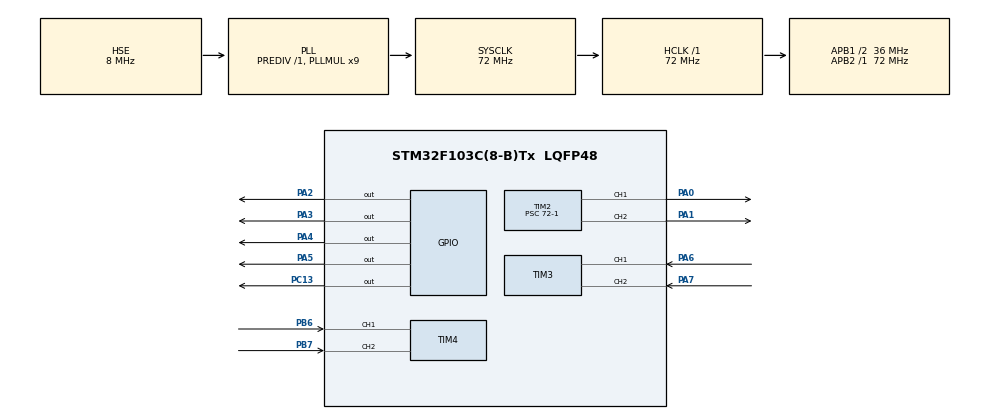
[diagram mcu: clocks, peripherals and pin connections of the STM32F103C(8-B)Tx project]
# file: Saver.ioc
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FREERTOS.Tasks01=defaultTask,0,128,StartDefaultTask,Default,NULL,Dynamic,NULL,NULL
Mcu.Family=STM32F1
Mcu.Name=STM32F103C(8-B)Tx
Mcu.Package=LQFP48
NVIC.PriorityGroup=NVIC_PRIORITYGROUP_4
NVIC.TIM3_IRQn=true\:5\:0\:false\:false\:true\:true\:true\:true\:true
NVIC.TIM4_IRQn=true\:5\:0\:false\:false\:true\:true\:true\:true\:true
PA0-WKUP.Signal=S_TIM2_CH1_ETR
PA1.Signal=S_TIM2_CH2
PA13.Mode=Serial_Wire
PA13.Signal=SYS_JTMS-SWDIO
PA14.Mode=Serial_Wire
PA14.Signal=SYS_JTCK-SWCLK
PA2.Signal=GPIO_Output
PA3.Signal=GPIO_Output
PA4.Signal=GPIO_Output
PA5.Signal=GPIO_Output
PA6.Signal=S_TIM3_CH1
PA7.Signal=S_TIM3_CH2
PB6.Signal=S_TIM4_CH1
PB7.Signal=S_TIM4_CH2
PC13-TAMPER-RTC.Signal=GPIO_Output
PD0-OSC_IN.Mode=HSE-External-Oscillator
PD0-OSC_IN.Signal=RCC_OSC_IN
PD1-OSC_OUT.Mode=HSE-External-Oscillator
PD1-OSC_OUT.Signal=RCC_OSC_OUT
ProjectManager.HeapSize=0x200
ProjectManager.StackSize=0x400
ProjectManager.TargetToolchain=MDK-ARM V5.32
RCC.AHBFreq_Value=72000000
RCC.APB1CLKDivider=RCC_HCLK_DIV2
RCC.APB1Freq_Value=36000000
RCC.APB1TimFreq_Value=72000000
RCC.APB2Freq_Value=72000000
RCC.APB2TimFreq_Value=72000000
RCC.HCLKFreq_Value=72000000
RCC.PLLMUL=RCC_PLL_MUL9
RCC.PLLSourceVirtual=RCC_PLLSOURCE_HSE
RCC.SYSCLKFreq_VALUE=72000000
RCC.SYSCLKSource=RCC_SYSCLKSOURCE_PLLCLK
RCC.USBFreq_Value=72000000
SH.S_TIM2_CH1_ETR.0=TIM2_CH1,PWM Generation1 CH1
SH.S_TIM2_CH2.0=TIM2_CH2,PWM Generation2 CH2
SH.S_TIM3_CH1.0=TIM3_CH1,Encoder_Interface
SH.S_TIM3_CH2.0=TIM3_CH2,Encoder_Interface
SH.S_TIM4_CH1.0=TIM4_CH1,Encoder_Interface
SH.S_TIM4_CH2.0=TIM4_CH2,Encoder_Interface
TIM2.Channel-PWM\ Generation1\ CH1=TIM_CHANNEL_1
TIM2.Channel-PWM\ Generation2\ CH2=TIM_CHANNEL_2
TIM2.Period=2000-1
TIM2.Prescaler=72-1
TIM3.EncoderMode=TIM_ENCODERMODE_TI12
TIM4.EncoderMode=TIM_ENCODERMODE_TI12
VP_FREERTOS_VS_CMSIS_V1.Mode=CMSIS_V1
board=custom

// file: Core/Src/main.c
/* USER CODE BEGIN Header */
/**
  ******************************************************************************
  * @file           : main.c
  * @brief          : Main program body
  ******************************************************************************
  * @attention
  *
  * Copyright (c) 2024 STMicroelectronics.
  * All rights reserved.
  *
  * This software is licensed under terms that can be found in the LICENSE file
  * in the root directory of this software component.
  * If no LICENSE file comes with this software, it is provided AS-IS.
  *
  ******************************************************************************
  */
/* USER CODE END Header */
#include "main.h"
#include "cmsis_os.h"
#include "tim.h"
#include "gpio.h"

void SystemClock_Config(void);
void MX_FREERTOS_Init(void);

int main(void)
{

  /* MCU Configuration--------------------------------------------------------*/

  /* Reset of all peripherals, Initializes the Flash interface and the Systick. */
  HAL_Init();

  /* Configure the system clock */
  SystemClock_Config();

  /* Initialize all configured peripherals */
  MX_GPIO_Init();
  MX_TIM2_Init();
  MX_TIM3_Init();
  MX_TIM4_Init();

  /* Call init function for freertos objects (in cmsis_os2.c) */
  MX_FREERTOS_Init();

  /* Start scheduler */
  osKernelStart();

  /* We should never get here as control is now taken by the scheduler */

  /* Infinite loop */
  while (1)
  {

  }
}

void SystemClock_Config(void)
{
  RCC_OscInitTypeDef RCC_OscInitStruct = {0};
  RCC_ClkInitTypeDef RCC_ClkInitStruct = {0};

  /** Initializes the RCC Oscillators according to the specified parameters
  * in the RCC_OscInitTypeDef structure.
  */
  RCC_OscInitStruct.OscillatorType = RCC_OSCILLATORTYPE_HSE;
  RCC_OscInitStruct.HSEState = RCC_HSE_ON;
  RCC_OscInitStruct.HSEPredivValue = RCC_HSE_PREDIV_DIV1;
  RCC_OscInitStruct.HSIState = RCC_HSI_ON;
  RCC_OscInitStruct.PLL.PLLState = RCC_PLL_ON;
  RCC_OscInitStruct.PLL.PLLSource = RCC_PLLSOURCE_HSE;
  RCC_OscInitStruct.PLL.PLLMUL = RCC_PLL_MUL9;
  if (HAL_RCC_OscConfig(&RCC_OscInitStruct) != HAL_OK)
  {
    Error_Handler();
  }

  /** Initializes the CPU, AHB and APB buses clocks
  */
  RCC_ClkInitStruct.ClockType = RCC_CLOCKTYPE_HCLK|RCC_CLOCKTYPE_SYSCLK
                              |RCC_CLOCKTYPE_PCLK1|RCC_CLOCKTYPE_PCLK2;
  RCC_ClkInitStruct.SYSCLKSource = RCC_SYSCLKSOURCE_PLLCLK;
  RCC_ClkInitStruct.AHBCLKDivider = RCC_SYSCLK_DIV1;
  RCC_ClkInitStruct.APB1CLKDivider = RCC_HCLK_DIV2;
  RCC_ClkInitStruct.APB2CLKDivider = RCC_HCLK_DIV1;

  if (HAL_RCC_ClockConfig(&RCC_ClkInitStruct, FLASH_LATENCY_2) != HAL_OK)
  {
    Error_Handler();
  }
}

void Error_Handler(void)
{
  __disable_irq();
  while (1)
  {
  }
}

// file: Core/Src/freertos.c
/* USER CODE BEGIN Header */
/**
  ******************************************************************************
  * File Name          : freertos.c
  * Description        : Code for freertos applications
  ******************************************************************************
  * @attention
  *
  * Copyright (c) 2024 STMicroelectronics.
  * All rights reserved.
  *
  * This software is licensed under terms that can be found in the LICENSE file
  * in the root directory of this software component.
  * If no LICENSE file comes with this software, it is provided AS-IS.
  *
  ******************************************************************************
  */
/* USER CODE END Header */

#include "FreeRTOS.h"
#include "task.h"
#include "main.h"
#include "cmsis_os.h"

/* USER CODE BEGIN Includes */
#include "motor.h"
#include "chassis.h"
#include "encoder.h"
/* USER CODE END Includes */

osThreadId defaultTaskHandle;

/* USER CODE BEGIN FunctionPrototypes */
osThreadId motorTaskHandle;
osThreadId chassisTaskHandle;
osThreadId encoderTaskHandle;
/* USER CODE END FunctionPrototypes */

void StartDefaultTask(void const * argument);

void MX_FREERTOS_Init(void); /* (MISRA C 2004 rule 8.1) */

/* GetIdleTaskMemory prototype (linked to static allocation support) */
void vApplicationGetIdleTaskMemory( StaticTask_t **ppxIdleTaskTCBBuffer, StackType_t **ppxIdleTaskStackBuffer, uint32_t *pulIdleTaskStackSize );

/* USER CODE BEGIN GET_IDLE_TASK_MEMORY */
static StaticTask_t xIdleTaskTCBBuffer;
static StackType_t xIdleStack[configMINIMAL_STACK_SIZE];

void vApplicationGetIdleTaskMemory( StaticTask_t **ppxIdleTaskTCBBuffer, StackType_t **ppxIdleTaskStackBuffer, uint32_t *pulIdleTaskStackSize )
{
  *ppxIdleTaskTCBBuffer = &xIdleTaskTCBBuffer;
  *ppxIdleTaskStackBuffer = &xIdleStack[0];
  *pulIdleTaskStackSize = configMINIMAL_STACK_SIZE;
  /* place for user code */
}
/* USER CODE END GET_IDLE_TASK_MEMORY */

void MX_FREERTOS_Init(void) {

  /* Create the thread(s) */
  /* definition and creation of defaultTask */
  osThreadDef(defaultTask, StartDefaultTask, osPriorityNormal, 0, 128);
  defaultTaskHandle = osThreadCreate(osThread(defaultTask), NULL);

  /* USER CODE BEGIN RTOS_THREADS */
  /* add threads, ... */
	osThreadDef(motorTask, Motor_task, osPriorityNormal, 0, 64);
  motorTaskHandle = osThreadCreate(osThread(motorTask), NULL);

	osThreadDef(encoderTask, Encoder_task, osPriorityNormal, 0, 64);
  encoderTaskHandle = osThreadCreate(osThread(encoderTask), NULL);

	osThreadDef(chassisTask, Chassis_task, osPriorityNormal, 0, 128);
  chassisTaskHandle = osThreadCreate(osThread(chassisTask), NULL);

  /* USER CODE END RTOS_THREADS */

}

void StartDefaultTask(void const * argument)
{
  /* USER CODE BEGIN StartDefaultTask */
  /* Infinite loop */
  for(;;)
  {
		HAL_GPIO_TogglePin(GPIOC, GPIO_PIN_13);
    osDelay(500);
  }
  /* USER CODE END StartDefaultTask */
}
